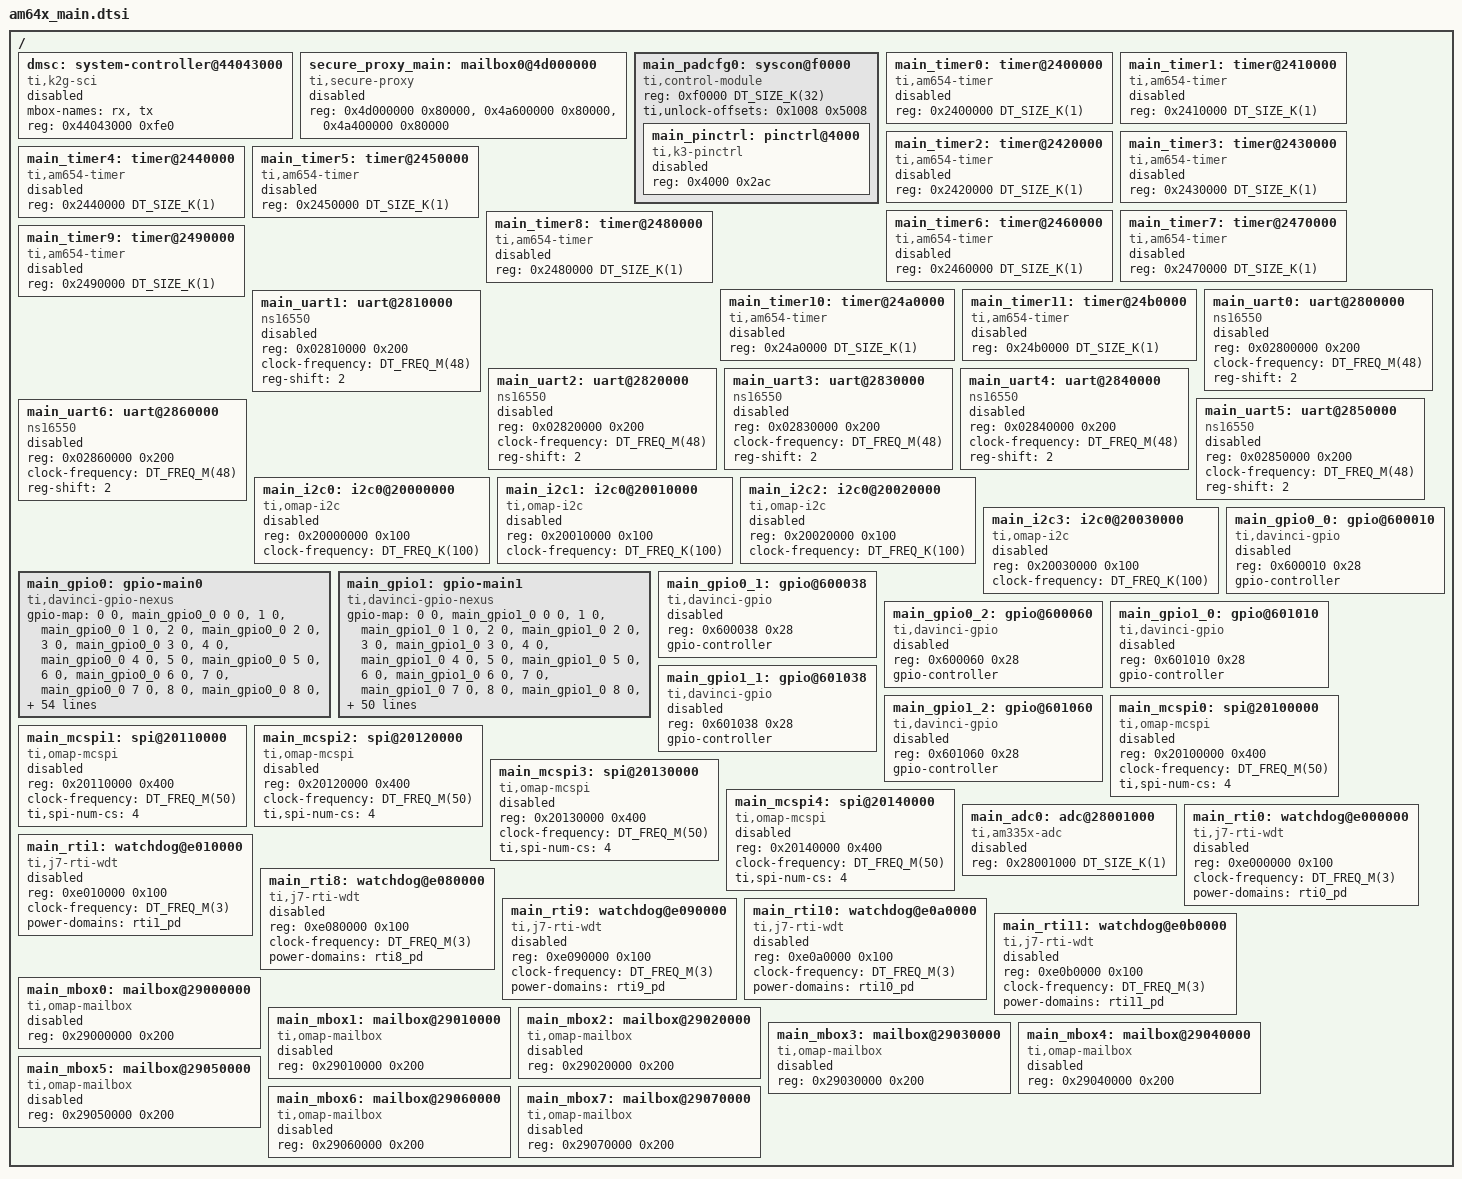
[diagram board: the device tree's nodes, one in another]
/*
 * Copyright (c) 2025 Texas Instruments Incorporated
 * Copyright (c) 2026 Siemens Mobility GmbH
 *
 * SPDX-License-Identifier: Apache-2.0
 */

#include <freq.h>
#include "am64x_main_power_domains.dtsi"

/ {
	#address-cells = <1>;
	#size-cells = <1>;

	dmsc: system-controller@44043000 {
		compatible = "ti,k2g-sci";
		mbox-names = "rx", "tx";
		reg-names = "debug_messages";
		reg = <0x44043000 0xfe0>;
		status = "disabled";
	};

	secure_proxy_main: mailbox0@4d000000 {
		compatible = "ti,secure-proxy";
		reg-names = "target_data", "rt", "scfg";
		reg = <0x4d000000 0x80000>, <0x4a600000 0x80000>, <0x4a400000 0x80000>;
		#mbox-cells = <1>;
		status = "disabled";
	};

	main_padcfg0: syscon@f0000 {
		compatible = "ti,control-module";
		reg = <0xf0000 DT_SIZE_K(32)>;
		ranges = <0x00 0xf0000 DT_SIZE_K(32)>;
		ti,unlock-offsets = <0x1008 0x5008>;
		#address-cells = <1>;
		#size-cells = <1>;

		main_pinctrl: pinctrl@4000 {
			compatible = "ti,k3-pinctrl";
			reg = <0x4000 0x2ac>;
			status = "disabled";
		};
	};

	main_timer0: timer@2400000 {
		compatible = "ti,am654-timer";
		reg = <0x2400000 DT_SIZE_K(1)>;
		status = "disabled";
	};

	main_timer1: timer@2410000 {
		compatible = "ti,am654-timer";
		reg = <0x2410000 DT_SIZE_K(1)>;
		status = "disabled";
	};

	main_timer2: timer@2420000 {
		compatible = "ti,am654-timer";
		reg = <0x2420000 DT_SIZE_K(1)>;
		status = "disabled";
	};

	main_timer3: timer@2430000 {
		compatible = "ti,am654-timer";
		reg = <0x2430000 DT_SIZE_K(1)>;
		status = "disabled";
	};

	main_timer4: timer@2440000 {
		compatible = "ti,am654-timer";
		reg = <0x2440000 DT_SIZE_K(1)>;
		status = "disabled";
	};

	main_timer5: timer@2450000 {
		compatible = "ti,am654-timer";
		reg = <0x2450000 DT_SIZE_K(1)>;
		status = "disabled";
	};

	main_timer6: timer@2460000 {
		compatible = "ti,am654-timer";
		reg = <0x2460000 DT_SIZE_K(1)>;
		status = "disabled";
	};

	main_timer7: timer@2470000 {
		compatible = "ti,am654-timer";
		reg = <0x2470000 DT_SIZE_K(1)>;
		status = "disabled";
	};

	main_timer8: timer@2480000 {
		compatible = "ti,am654-timer";
		reg = <0x2480000 DT_SIZE_K(1)>;
		status = "disabled";
	};

	main_timer9: timer@2490000 {
		compatible = "ti,am654-timer";
		reg = <0x2490000 DT_SIZE_K(1)>;
		status = "disabled";
	};

	main_timer10: timer@24a0000 {
		compatible = "ti,am654-timer";
		reg = <0x24a0000 DT_SIZE_K(1)>;
		status = "disabled";
	};

	main_timer11: timer@24b0000 {
		compatible = "ti,am654-timer";
		reg = <0x24b0000 DT_SIZE_K(1)>;
		status = "disabled";
	};

	main_uart0: uart@2800000 {
		compatible = "ns16550";
		reg = <0x02800000 0x200>;
		clock-frequency = <DT_FREQ_M(48)>;
		reg-shift = <2>;
		status = "disabled";
	};

	main_uart1: uart@2810000 {
		compatible = "ns16550";
		reg = <0x02810000 0x200>;
		clock-frequency = <DT_FREQ_M(48)>;
		reg-shift = <2>;
		status = "disabled";
	};

	main_uart2: uart@2820000 {
		compatible = "ns16550";
		reg = <0x02820000 0x200>;
		clock-frequency = <DT_FREQ_M(48)>;
		reg-shift = <2>;
		status = "disabled";
	};

	main_uart3: uart@2830000 {
		compatible = "ns16550";
		reg = <0x02830000 0x200>;
		clock-frequency = <DT_FREQ_M(48)>;
		reg-shift = <2>;
		status = "disabled";
	};

	main_uart4: uart@2840000 {
		compatible = "ns16550";
		reg = <0x02840000 0x200>;
		clock-frequency = <DT_FREQ_M(48)>;
		reg-shift = <2>;
		status = "disabled";
	};

	main_uart5: uart@2850000 {
		compatible = "ns16550";
		reg = <0x02850000 0x200>;
		clock-frequency = <DT_FREQ_M(48)>;
		reg-shift = <2>;
		status = "disabled";
	};

	main_uart6: uart@2860000 {
		compatible = "ns16550";
		reg = <0x02860000 0x200>;
		clock-frequency = <DT_FREQ_M(48)>;
		reg-shift = <2>;
		status = "disabled";
	};

	main_i2c0: i2c0@20000000 {
		compatible = "ti,omap-i2c";
		reg = <0x20000000 0x100>;
		clock-frequency = <DT_FREQ_K(100)>;
		#address-cells = <1>;
		#size-cells = <0>;
		status = "disabled";
	};

	main_i2c1: i2c0@20010000 {
		compatible = "ti,omap-i2c";
		reg = <0x20010000 0x100>;
		clock-frequency = <DT_FREQ_K(100)>;
		#address-cells = <1>;
		#size-cells = <0>;
		status = "disabled";
	};

	main_i2c2: i2c0@20020000 {
		compatible = "ti,omap-i2c";
		reg = <0x20020000 0x100>;
		clock-frequency = <DT_FREQ_K(100)>;
		#address-cells = <1>;
		#size-cells = <0>;
		status = "disabled";
	};

	main_i2c3: i2c0@20030000 {
		compatible = "ti,omap-i2c";
		reg = <0x20030000 0x100>;
		clock-frequency = <DT_FREQ_K(100)>;
		#address-cells = <1>;
		#size-cells = <0>;
		status = "disabled";
	};

	main_gpio0: gpio-main0 {
		compatible = "ti,davinci-gpio-nexus";
		#gpio-cells = <2>;
		gpio-map = <0 0 &main_gpio0_0 0 0>, <1 0 &main_gpio0_0 1 0>,
			   <2 0 &main_gpio0_0 2 0>, <3 0 &main_gpio0_0 3 0>,
			   <4 0 &main_gpio0_0 4 0>, <5 0 &main_gpio0_0 5 0>,
			   <6 0 &main_gpio0_0 6 0>, <7 0 &main_gpio0_0 7 0>,
			   <8 0 &main_gpio0_0 8 0>, <9 0 &main_gpio0_0 9 0>,
			   <10 0 &main_gpio0_0 10 0>, <11 0 &main_gpio0_0 11 0>,
			   <12 0 &main_gpio0_0 12 0>, <13 0 &main_gpio0_0 13 0>,
			   <14 0 &main_gpio0_0 14 0>, <15 0 &main_gpio0_0 15 0>,
			   <16 0 &main_gpio0_0 16 0>, <17 0 &main_gpio0_0 17 0>,
			   <18 0 &main_gpio0_0 18 0>, <19 0 &main_gpio0_0 19 0>,
			   <20 0 &main_gpio0_0 20 0>, <21 0 &main_gpio0_0 21 0>,
			   <22 0 &main_gpio0_0 22 0>, <23 0 &main_gpio0_0 23 0>,
			   <24 0 &main_gpio0_0 24 0>, <25 0 &main_gpio0_0 25 0>,
			   <26 0 &main_gpio0_0 26 0>, <27 0 &main_gpio0_0 27 0>,
			   <28 0 &main_gpio0_0 28 0>, <29 0 &main_gpio0_0 29 0>,
			   <30 0 &main_gpio0_0 30 0>, <31 0 &main_gpio0_0 31 0>,
			   <32 0 &main_gpio0_1 0 0>, <33 0 &main_gpio0_1 1 0>,
			   <34 0 &main_gpio0_1 2 0>, <35 0 &main_gpio0_1 3 0>,
			   <36 0 &main_gpio0_1 4 0>, <37 0 &main_gpio0_1 5 0>,
			   <38 0 &main_gpio0_1 6 0>, <39 0 &main_gpio0_1 7 0>,
			   <40 0 &main_gpio0_1 8 0>, <41 0 &main_gpio0_1 9 0>,
			   <42 0 &main_gpio0_1 10 0>, <43 0 &main_gpio0_1 11 0>,
			   <44 0 &main_gpio0_1 12 0>, <45 0 &main_gpio0_1 13 0>,
			   <46 0 &main_gpio0_1 14 0>, <47 0 &main_gpio0_1 15 0>,
			   <48 0 &main_gpio0_1 16 0>, <49 0 &main_gpio0_1 17 0>,
			   <50 0 &main_gpio0_1 18 0>, <51 0 &main_gpio0_1 19 0>,
			   <52 0 &main_gpio0_1 20 0>, <53 0 &main_gpio0_1 21 0>,
			   <54 0 &main_gpio0_1 22 0>, <55 0 &main_gpio0_1 23 0>,
			   <56 0 &main_gpio0_1 24 0>, <57 0 &main_gpio0_1 25 0>,
			   <58 0 &main_gpio0_1 26 0>, <59 0 &main_gpio0_1 27 0>,
			   <60 0 &main_gpio0_1 28 0>, <61 0 &main_gpio0_1 29 0>,
			   <62 0 &main_gpio0_1 30 0>, <63 0 &main_gpio0_1 31 0>,
			   <64 0 &main_gpio0_2 0 0>, <65 0 &main_gpio0_2 1 0>,
			   <66 0 &main_gpio0_2 2 0>, <67 0 &main_gpio0_2 3 0>,
			   <68 0 &main_gpio0_2 4 0>, <69 0 &main_gpio0_2 5 0>,
			   <70 0 &main_gpio0_2 6 0>, <71 0 &main_gpio0_2 7 0>,
			   <72 0 &main_gpio0_2 8 0>, <73 0 &main_gpio0_2 9 0>,
			   <74 0 &main_gpio0_2 10 0>, <75 0 &main_gpio0_2 11 0>,
			   <76 0 &main_gpio0_2 12 0>, <77 0 &main_gpio0_2 13 0>,
			   <78 0 &main_gpio0_2 14 0>, <79 0 &main_gpio0_2 15 0>,
			   <80 0 &main_gpio0_2 16 0>, <81 0 &main_gpio0_2 17 0>,
			   <82 0 &main_gpio0_2 18 0>, <83 0 &main_gpio0_2 19 0>,
			   <84 0 &main_gpio0_2 20 0>, <85 0 &main_gpio0_2 21 0>,
			   <86 0 &main_gpio0_2 22 0>;
		gpio-map-mask = <0xffff 0x0>;
		gpio-map-pass-thru = <0x0 0x1>;
	};

	main_gpio1: gpio-main1 {
		compatible = "ti,davinci-gpio-nexus";
		#gpio-cells = <2>;
		gpio-map = <0 0 &main_gpio1_0 0 0>, <1 0 &main_gpio1_0 1 0>,
			   <2 0 &main_gpio1_0 2 0>, <3 0 &main_gpio1_0 3 0>,
			   <4 0 &main_gpio1_0 4 0>, <5 0 &main_gpio1_0 5 0>,
			   <6 0 &main_gpio1_0 6 0>, <7 0 &main_gpio1_0 7 0>,
			   <8 0 &main_gpio1_0 8 0>, <9 0 &main_gpio1_0 9 0>,
			   <10 0 &main_gpio1_0 10 0>, <11 0 &main_gpio1_0 11 0>,
			   <12 0 &main_gpio1_0 12 0>, <13 0 &main_gpio1_0 13 0>,
			   <14 0 &main_gpio1_0 14 0>, <15 0 &main_gpio1_0 15 0>,
			   <16 0 &main_gpio1_0 16 0>, <17 0 &main_gpio1_0 17 0>,
			   <18 0 &main_gpio1_0 18 0>, <19 0 &main_gpio1_0 19 0>,
			   <20 0 &main_gpio1_0 20 0>, <21 0 &main_gpio1_0 21 0>,
			   <22 0 &main_gpio1_0 22 0>, <23 0 &main_gpio1_0 23 0>,
			   <24 0 &main_gpio1_0 24 0>, <25 0 &main_gpio1_0 25 0>,
			   <26 0 &main_gpio1_0 26 0>, <27 0 &main_gpio1_0 27 0>,
			   <28 0 &main_gpio1_0 28 0>, <29 0 &main_gpio1_0 29 0>,
			   <30 0 &main_gpio1_0 30 0>, <31 0 &main_gpio1_0 31 0>,
			   <32 0 &main_gpio1_1 0 0>, <33 0 &main_gpio1_1 1 0>,
			   <34 0 &main_gpio1_1 2 0>, <35 0 &main_gpio1_1 3 0>,
			   <36 0 &main_gpio1_1 4 0>, <37 0 &main_gpio1_1 5 0>,
			   <38 0 &main_gpio1_1 6 0>, <39 0 &main_gpio1_1 7 0>,
			   <40 0 &main_gpio1_1 8 0>, <41 0 &main_gpio1_1 9 0>,
			   <42 0 &main_gpio1_1 10 0>, <43 0 &main_gpio1_1 11 0>,
			   <44 0 &main_gpio1_1 12 0>, <45 0 &main_gpio1_1 13 0>,
			   <46 0 &main_gpio1_1 14 0>, <47 0 &main_gpio1_1 15 0>,
			   <48 0 &main_gpio1_1 16 0>, <49 0 &main_gpio1_1 17 0>,
			   <50 0 &main_gpio1_1 18 0>, <51 0 &main_gpio1_1 19 0>,
			   <52 0 &main_gpio1_1 20 0>, <53 0 &main_gpio1_1 21 0>,
			   <54 0 &main_gpio1_1 22 0>, <55 0 &main_gpio1_1 23 0>,
			   <56 0 &main_gpio1_1 24 0>, <57 0 &main_gpio1_1 25 0>,
			   <58 0 &main_gpio1_1 26 0>, <59 0 &main_gpio1_1 27 0>,
			   <60 0 &main_gpio1_1 28 0>, <61 0 &main_gpio1_1 29 0>,
			   <62 0 &main_gpio1_1 30 0>, <63 0 &main_gpio1_1 31 0>,
			   <64 0 &main_gpio1_2 0 0>, <65 0 &main_gpio1_2 1 0>,
			   <66 0 &main_gpio1_2 2 0>, <67 0 &main_gpio1_2 3 0>,
			   <68 0 &main_gpio1_2 4 0>, <69 0 &main_gpio1_2 5 0>,
			   <70 0 &main_gpio1_2 6 0>, <71 0 &main_gpio1_2 7 0>,
			   <72 0 &main_gpio1_2 8 0>, <73 0 &main_gpio1_2 9 0>,
			   <74 0 &main_gpio1_2 10 0>, <75 0 &main_gpio1_2 11 0>,
			   <76 0 &main_gpio1_2 12 0>, <77 0 &main_gpio1_2 13 0>,
			   <78 0 &main_gpio1_2 14 0>, <79 0 &main_gpio1_2 15 0>;
		gpio-map-mask = <0xffff 0x0>;
		gpio-map-pass-thru = <0x0 0x1>;
	};

	main_gpio0_0: gpio@600010 {
		compatible = "ti,davinci-gpio";
		reg = <0x600010 0x28>;
		gpio-controller;
		#gpio-cells = <2>;
		status = "disabled";
	};

	main_gpio0_1: gpio@600038 {
		compatible = "ti,davinci-gpio";
		reg = <0x600038 0x28>;
		gpio-controller;
		#gpio-cells = <2>;
		status = "disabled";
	};

	main_gpio0_2: gpio@600060 {
		compatible = "ti,davinci-gpio";
		reg = <0x600060 0x28>;
		gpio-controller;
		#gpio-cells = <2>;
		status = "disabled";
	};

	main_gpio1_0: gpio@601010 {
		compatible = "ti,davinci-gpio";
		reg = <0x601010 0x28>;
		gpio-controller;
		#gpio-cells = <2>;
		status = "disabled";
	};

	main_gpio1_1: gpio@601038 {
		compatible = "ti,davinci-gpio";
		reg = <0x601038 0x28>;
		gpio-controller;
		#gpio-cells = <2>;
		status = "disabled";
	};

	main_gpio1_2: gpio@601060 {
		compatible = "ti,davinci-gpio";
		reg = <0x601060 0x28>;
		gpio-controller;
		#gpio-cells = <2>;
		status = "disabled";
	};

	main_mcspi0: spi@20100000 {
		compatible = "ti,omap-mcspi";
		reg = <0x20100000 0x400>;
		clock-frequency = <DT_FREQ_M(50)>;
		ti,spi-num-cs = <4>;
		#address-cells = <1>;
		#size-cells = <0>;
		status = "disabled";
	};

	main_mcspi1: spi@20110000 {
		compatible = "ti,omap-mcspi";
		reg = <0x20110000 0x400>;
		clock-frequency = <DT_FREQ_M(50)>;
		ti,spi-num-cs = <4>;
		#address-cells = <1>;
		#size-cells = <0>;
		status = "disabled";
	};

	main_mcspi2: spi@20120000 {
		compatible = "ti,omap-mcspi";
		reg = <0x20120000 0x400>;
		clock-frequency = <DT_FREQ_M(50)>;
		ti,spi-num-cs = <4>;
		#address-cells = <1>;
		#size-cells = <0>;
		status = "disabled";
	};

	main_mcspi3: spi@20130000 {
		compatible = "ti,omap-mcspi";
		reg = <0x20130000 0x400>;
		clock-frequency = <DT_FREQ_M(50)>;
		ti,spi-num-cs = <4>;
		#address-cells = <1>;
		#size-cells = <0>;
		status = "disabled";
	};

	main_mcspi4: spi@20140000 {
		compatible = "ti,omap-mcspi";
		reg = <0x20140000 0x400>;
		clock-frequency = <DT_FREQ_M(50)>;
		ti,spi-num-cs = <4>;
		#address-cells = <1>;
		#size-cells = <0>;
		status = "disabled";
	};

	main_adc0: adc@28001000 {
		compatible = "ti,am335x-adc";
		reg = <0x28001000 DT_SIZE_K(1)>;
		status = "disabled";
		#io-channel-cells = <1>;
		#address-cells = <1>;
		#size-cells = <0>;
	};

	main_rti0: watchdog@e000000 {
		compatible = "ti,j7-rti-wdt";
		reg = <0xe000000 0x100>;
		clock-frequency = <DT_FREQ_M(3)>;
		power-domains = <&rti0_pd>;
		status = "disabled";
	};

	main_rti1: watchdog@e010000 {
		compatible = "ti,j7-rti-wdt";
		reg = <0xe010000 0x100>;
		clock-frequency = <DT_FREQ_M(3)>;
		power-domains = <&rti1_pd>;
		status = "disabled";
	};

	main_rti8: watchdog@e080000 {
		compatible = "ti,j7-rti-wdt";
		reg = <0xe080000 0x100>;
		clock-frequency = <DT_FREQ_M(3)>;
		power-domains = <&rti8_pd>;
		status = "disabled";
	};

	main_rti9: watchdog@e090000 {
		compatible = "ti,j7-rti-wdt";
		reg = <0xe090000 0x100>;
		clock-frequency = <DT_FREQ_M(3)>;
		power-domains = <&rti9_pd>;
		status = "disabled";
	};

	main_rti10: watchdog@e0a0000 {
		compatible = "ti,j7-rti-wdt";
		reg = <0xe0a0000 0x100>;
		clock-frequency = <DT_FREQ_M(3)>;
		power-domains = <&rti10_pd>;
		status = "disabled";
	};

	main_rti11: watchdog@e0b0000 {
		compatible = "ti,j7-rti-wdt";
		reg = <0xe0b0000 0x100>;
		clock-frequency = <DT_FREQ_M(3)>;
		power-domains = <&rti11_pd>;
		status = "disabled";
	};

	/* users: r5f0_0, r5f0_1, r5f1_0, r5f1_1 */
	main_mbox0: mailbox@29000000 {
		compatible = "ti,omap-mailbox";
		reg = <0x29000000 0x200>;
		#mbox-cells = <1>;
		status = "disabled";
	};

	/* users: r5f0_0, r5f0_1, r5f1_0, r5f1_1 */
	main_mbox1: mailbox@29010000 {
		compatible = "ti,omap-mailbox";
		reg = <0x29010000 0x200>;
		#mbox-cells = <1>;
		status = "disabled";
	};

	/* users: r5f0_0, r5f0_1, a53 */
	main_mbox2: mailbox@29020000 {
		compatible = "ti,omap-mailbox";
		reg = <0x29020000 0x200>;
		#mbox-cells = <1>;
		status = "disabled";
	};

	/* users: r5f0_0, r5f0_1, a53 */
	main_mbox3: mailbox@29030000 {
		compatible = "ti,omap-mailbox";
		reg = <0x29030000 0x200>;
		#mbox-cells = <1>;
		status = "disabled";
	};

	/* users: r5f1_0, r5f1_1, a53 */
	main_mbox4: mailbox@29040000 {
		compatible = "ti,omap-mailbox";
		reg = <0x29040000 0x200>;
		#mbox-cells = <1>;
		status = "disabled";
	};

	/* users: r5f1_0, r5f1_1, a53 */
	main_mbox5: mailbox@29050000 {
		compatible = "ti,omap-mailbox";
		reg = <0x29050000 0x200>;
		#mbox-cells = <1>;
		status = "disabled";
	};

	/* users: r5f0_0, r5f0_1, a53, m4 */
	main_mbox6: mailbox@29060000 {
		compatible = "ti,omap-mailbox";
		reg = <0x29060000 0x200>;
		#mbox-cells = <1>;
		status = "disabled";
	};

	/* users: r5f1_0, r5f1_1, a53, m4 */
	main_mbox7: mailbox@29070000 {
		compatible = "ti,omap-mailbox";
		reg = <0x29070000 0x200>;
		#mbox-cells = <1>;
		status = "disabled";
	};
};
